# DEBUGSS_WRAP_DRM_CFG_1_000760002000h register map
Vendor: Texas Instruments
Peripheral module from a debugger description file (folder AM275x).
Registers are 32-bit, read-write, reset values left out (the file's numbers can be read two ways) unless marked. A register's access mark holds for its fields unless they carry their own. Offsets are as the file gives them; lines under a group give offsets from that group; [hi:lo] are bit positions; {n}, {i} and the like mark numbered series; 'fields as' and 'values as' point back to an identical list; <NAME> marks a mode.

## drm_cfg_1
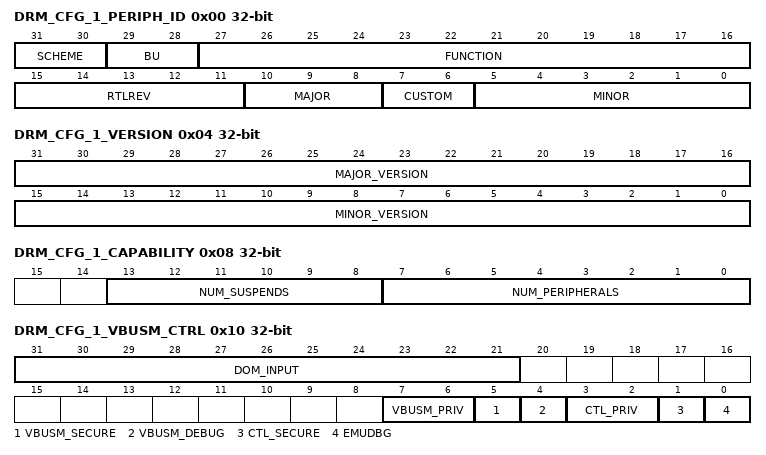
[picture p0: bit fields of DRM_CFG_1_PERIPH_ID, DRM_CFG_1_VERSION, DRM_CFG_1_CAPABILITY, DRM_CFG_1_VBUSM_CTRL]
0x00 DRM_CFG_1_PERIPH_ID ro — This register is used to determine what the functionality of this peripheral is.
  [31:30] SCHEME — Peripheral ID Scheme [0]
  [29:28] BU — Reserved, returns 0
  [27:16] FUNCTION — DRM Function ID [0x211]
  [15:11] RTLREV — RTL Revision [0]
  [10:8] MAJOR — Major Peripheral Revision [0]
  [7:6] CUSTOM — Custon Peripheral ID version [0]
  [5:0] MINOR — Minor Peripheral Revision [0]
0x04 DRM_CFG_1_VERSION ro — This register is used to enable the Time Generator. For application access, the DTG must be unlocked first.
  [31:16] MAJOR_VERSION — Contains the major version value [1]
  [15:0] MINOR_VERSION — Contains the minor version value [0]
0x08 DRM_CFG_1_CAPABILITY ro — This register can be read to determine the number of suspend signals and number of peripherals.
  [13:8] NUM_SUSPENDS — Contains the number of Suspend signals supported, max of 32 There should be one signal per processor This value is set by a parameter at synthesis time
  [7:0] NUM_PERIPHERALS — Contains the number of peripherals supported, max of 128 This affects the number of SUSPEND_REG registers This is set by a parameter during synthesis
0x0C DRM_CFG_1_TRACE_CTRL access per field — This register is used to set the trace sampling mode to center(1) or edge(0).
  [0] CENTER_SAMPLING rw — Sets trace to center sampled
0x10 DRM_CFG_1_VBUSM_CTRL access per field — This register is used to set attributes on the VBUSM memory accesses and to read the Debug Operating Mode
  [31:21] DOM_INPUT ro — This returns the DOM security input The upper 3 bits are the debug operating mode and the lower 8 bits are the priviledge ID for VBUSM transaction
  [7:6] VBUSM_PRIV ro — These two bits show the currently state of the priv bits
  [5] VBUSM_SECURE ro — This bit shows the currently active state of the VBUSM secure bit
  [4] VBUSM_DEBUG ro — This is the currently active state of the VBUSM emudbg bit
  [3:2] CTL_PRIV rw — These two bits determine the priviledge type for VBUSM accesses unless overridden by the DOM input [0 is user level privilege, 1 is supervisor level privilege, 2 is hypervisor level privilege and 3 is reserved]
  [1] CTL_SECURE rw — When set [and DOM permits it], the VBUSM accesses will have the secure bit set
  [0] EMUDBG rw — Sets the emudbg bit during access to make the debug or non-debug
0x14 DRM_CFG_1_DAP_TIMEOUT — This register is used to set the maximum wait time for the DAP to complete a memory access.
  [31:0] DAP_TIMEOUT_REGISTER
0x18 DRM_CFG_1_CONFIG access per field — This register adds softreset capability to the suspend module.
  [0] SOFTRESET rw — Software controlled reset of the DRM
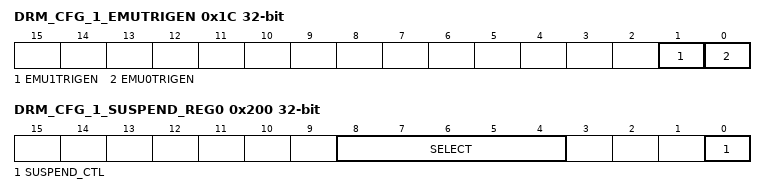
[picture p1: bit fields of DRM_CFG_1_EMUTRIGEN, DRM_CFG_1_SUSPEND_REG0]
0x1C DRM_CFG_1_EMUTRIGEN access per field — This register is used to enable EMU triggers.
  [1] EMU1TRIGEN rw — EMU 1 Trigger En
  [0] EMU0TRIGEN rw — EMU 0 Trigger En
0x20 DRM_CFG_1_BINVALLO — Reading this register returns the lower 32 bits of the binary debug time.
  [31:0] DTG_BINARY_TIME_LOW
0x24 DRM_CFG_1_BINVALHI ro — Reading this register returns the upper 16 bits of the binary debug time and causes the lower 32 bits to be latched.
  [14:0] BINTIMEHI — Upper 16 bits of the timer
0x200 DRM_CFG_1_SUSPEND_REG0 access per field — The DRM Suspend Registers merge the emulation suspend signals sent by various processors, when it wishes to suspend the activity of connected peripherals during debugging. There can be upto 128 of these registers (See NUM_PERIPHERALS in the DRM_CAPABILITY register)
  [8:4] SELECT rw — Selects which suspend control line [1-32] goes to the peripheral
  [0] SUSPEND_CTL rw — When 1, the peripheral is sensitive to the suspend signal, when 0, it ignore it
{0x200+4i} DRM_CFG_1_SUSPEND_REG{i} (i=1..31) — The DRM Suspend Registers merge the emulation suspend signals sent by various processors, when it wishes to suspend the activity of connected peripherals during debugging. See Suspend Reg 0 for details
  [31:0] SUSPEND_REG_{i} — See Suspend Reg 0 for field information
